# dsPIC33FJ64GS606 register map
Vendor: Microchip; Series: dsPIC33FJ64GS; File version: 1.4.228
Registers are 16-bit, read-write, no defined reset value unless marked. A register's access mark holds for its fields unless they carry their own. Offsets are from the block's base; [hi:lo] are bit positions; {n}, {i} and the like mark numbered series.

## PWM2 — PWM2 peripheral registers
Base 0x00000440
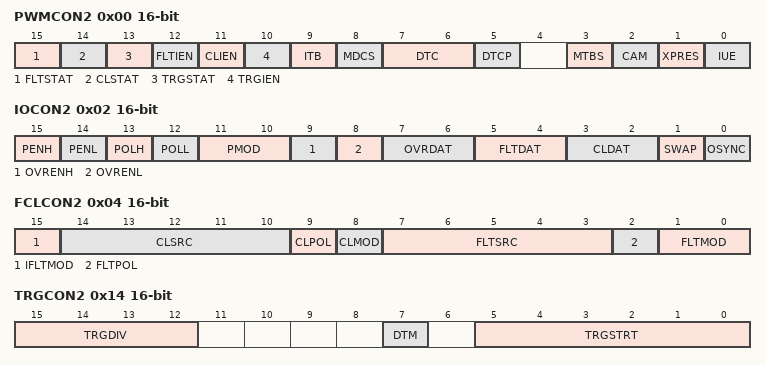
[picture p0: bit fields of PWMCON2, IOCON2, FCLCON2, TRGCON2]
0x00 PWMCON2
  [15] FLTSTAT — PWMCON2 field FLTSTAT
  [14] CLSTAT — PWMCON2 field CLSTAT
  [13] TRGSTAT — PWMCON2 field TRGSTAT
  [12] FLTIEN — PWMCON2 field FLTIEN
  [11] CLIEN — PWMCON2 field CLIEN
  [10] TRGIEN — PWMCON2 field TRGIEN
  [9] ITB — PWMCON2 field ITB
  [8] MDCS — PWMCON2 field MDCS
  [7:6] DTC — PWMCON2 field DTC
  [5] DTCP — PWMCON2 field DTCP
  [3] MTBS — PWMCON2 field MTBS
  [2] CAM — PWMCON2 field CAM
  [1] XPRES — PWMCON2 field XPRES
  [0] IUE — PWMCON2 field IUE
0x02 IOCON2
  [15] PENH — IOCON2 field PENH
  [14] PENL — IOCON2 field PENL
  [13] POLH — IOCON2 field POLH
  [12] POLL — IOCON2 field POLL
  [11:10] PMOD — IOCON2 field PMOD
  [9] OVRENH — IOCON2 field OVRENH
  [8] OVRENL — IOCON2 field OVRENL
  [7:6] OVRDAT — IOCON2 field OVRDAT
  [5:4] FLTDAT — IOCON2 field FLTDAT
  [3:2] CLDAT — IOCON2 field CLDAT
  [1] SWAP — IOCON2 field SWAP
  [0] OSYNC — IOCON2 field OSYNC
0x04 FCLCON2
  [15] IFLTMOD — FCLCON2 field IFLTMOD
  [14:10] CLSRC — FCLCON2 field CLSRC
  [9] CLPOL — FCLCON2 field CLPOL
  [8] CLMOD — FCLCON2 field CLMOD
  [7:3] FLTSRC — FCLCON2 field FLTSRC
  [2] FLTPOL — FCLCON2 field FLTPOL
  [1:0] FLTMOD — FCLCON2 field FLTMOD
0x06 PDC2
  [15:0] PDC2 — PDC2 register value
0x08 PHASE2
  [15:0] PHASE2 — PHASE2 register value
0x0A DTR2
  [13:0] DTR — DTR2 dead-time value
0x0C ALTDTR2
  [13:0] ALTDTR — ALTDTR2 dead-time value
0x0E SDC2
  [15:0] SDC2 — SDC2 register value
0x10 SPHASE2
  [15:0] SPHASE2 — SPHASE2 register value
0x12 TRIG2
  [15:3] TRGCMP — TRIG2 field TRGCMP
0x14 TRGCON2
  [15:12] TRGDIV — TRGCON2 field TRGDIV
  [7] DTM — TRGCON2 field DTM
  [5:0] TRGSTRT — TRGCON2 field TRGSTRT
0x16 STRIG2
  [15:3] STRGCMP — STRIG2 field STRGCMP
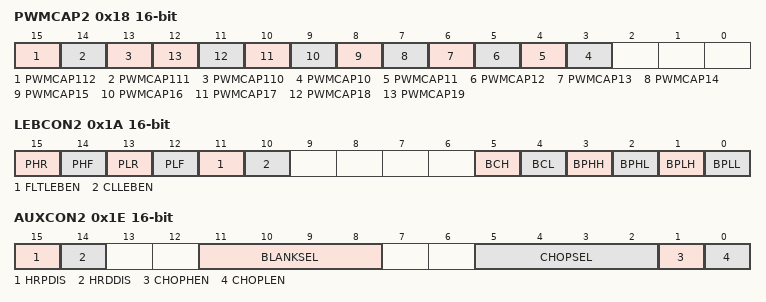
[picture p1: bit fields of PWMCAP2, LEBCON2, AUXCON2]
0x18 PWMCAP2
  [15] PWMCAP112 — PWMCAP2 field PWMCAP112
  [14] PWMCAP111 — PWMCAP2 field PWMCAP111
  [13] PWMCAP110 — PWMCAP2 field PWMCAP110
  [n-7] PWMCAP{n} (n=10..19) — PWMCAP2 field PWMCAP{n}
0x1A LEBCON2
  [15] PHR — LEBCON2 field PHR
  [14] PHF — LEBCON2 field PHF
  [13] PLR — LEBCON2 field PLR
  [12] PLF — LEBCON2 field PLF
  [11] FLTLEBEN — LEBCON2 field FLTLEBEN
  [10] CLLEBEN — LEBCON2 field CLLEBEN
  [5] BCH — LEBCON2 field BCH
  [4] BCL — LEBCON2 field BCL
  [3] BPHH — LEBCON2 field BPHH
  [2] BPHL — LEBCON2 field BPHL
  [1] BPLH — LEBCON2 field BPLH
  [0] BPLL — LEBCON2 field BPLL
0x1C LEBDLY2
  [11:3] LEB — LEBDLY2 field LEB
0x1E AUXCON2
  [15] HRPDIS — AUXCON2 field HRPDIS
  [14] HRDDIS — AUXCON2 field HRDDIS
  [11:8] BLANKSEL — AUXCON2 field BLANKSEL
  [5:2] CHOPSEL — AUXCON2 field CHOPSEL
  [1] CHOPHEN — AUXCON2 field CHOPHEN
  [0] CHOPLEN — AUXCON2 field CHOPLEN

## PWM3 — PWM3 peripheral registers
Base 0x00000460
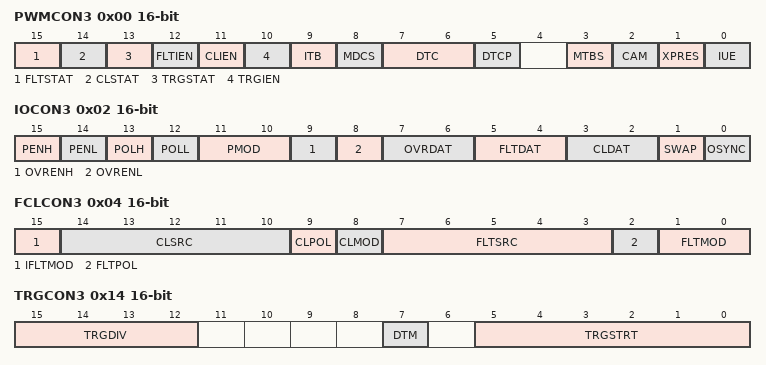
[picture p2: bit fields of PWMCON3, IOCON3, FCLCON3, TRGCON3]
0x00 PWMCON3
  [15] FLTSTAT — PWMCON3 field FLTSTAT
  [14] CLSTAT — PWMCON3 field CLSTAT
  [13] TRGSTAT — PWMCON3 field TRGSTAT
  [12] FLTIEN — PWMCON3 field FLTIEN
  [11] CLIEN — PWMCON3 field CLIEN
  [10] TRGIEN — PWMCON3 field TRGIEN
  [9] ITB — PWMCON3 field ITB
  [8] MDCS — PWMCON3 field MDCS
  [7:6] DTC — PWMCON3 field DTC
  [5] DTCP — PWMCON3 field DTCP
  [3] MTBS — PWMCON3 field MTBS
  [2] CAM — PWMCON3 field CAM
  [1] XPRES — PWMCON3 field XPRES
  [0] IUE — PWMCON3 field IUE
0x02 IOCON3
  [15] PENH — IOCON3 field PENH
  [14] PENL — IOCON3 field PENL
  [13] POLH — IOCON3 field POLH
  [12] POLL — IOCON3 field POLL
  [11:10] PMOD — IOCON3 field PMOD
  [9] OVRENH — IOCON3 field OVRENH
  [8] OVRENL — IOCON3 field OVRENL
  [7:6] OVRDAT — IOCON3 field OVRDAT
  [5:4] FLTDAT — IOCON3 field FLTDAT
  [3:2] CLDAT — IOCON3 field CLDAT
  [1] SWAP — IOCON3 field SWAP
  [0] OSYNC — IOCON3 field OSYNC
0x04 FCLCON3
  [15] IFLTMOD — FCLCON3 field IFLTMOD
  [14:10] CLSRC — FCLCON3 field CLSRC
  [9] CLPOL — FCLCON3 field CLPOL
  [8] CLMOD — FCLCON3 field CLMOD
  [7:3] FLTSRC — FCLCON3 field FLTSRC
  [2] FLTPOL — FCLCON3 field FLTPOL
  [1:0] FLTMOD — FCLCON3 field FLTMOD
0x06 PDC3
  [15:0] PDC3 — PDC3 register value
0x08 PHASE3
  [15:0] PHASE3 — PHASE3 register value
0x0A DTR3
  [13:0] DTR — DTR3 dead-time value
0x0C ALTDTR3
  [13:0] ALTDTR — ALTDTR3 dead-time value
0x0E SDC3
  [15:0] SDC3 — SDC3 register value
0x10 SPHASE3
  [15:0] SPHASE3 — SPHASE3 register value
0x12 TRIG3
  [15:3] TRGCMP — TRIG3 field TRGCMP
0x14 TRGCON3
  [15:12] TRGDIV — TRGCON3 field TRGDIV
  [7] DTM — TRGCON3 field DTM
  [5:0] TRGSTRT — TRGCON3 field TRGSTRT
0x16 STRIG3
  [15:3] STRGCMP — STRIG3 field STRGCMP
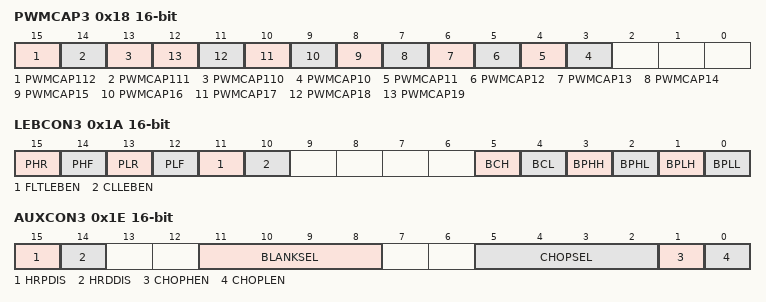
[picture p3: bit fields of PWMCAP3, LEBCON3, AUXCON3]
0x18 PWMCAP3
  [15] PWMCAP112 — PWMCAP3 field PWMCAP112
  [14] PWMCAP111 — PWMCAP3 field PWMCAP111
  [13] PWMCAP110 — PWMCAP3 field PWMCAP110
  [n-7] PWMCAP{n} (n=10..19) — PWMCAP3 field PWMCAP{n}
0x1A LEBCON3
  [15] PHR — LEBCON3 field PHR
  [14] PHF — LEBCON3 field PHF
  [13] PLR — LEBCON3 field PLR
  [12] PLF — LEBCON3 field PLF
  [11] FLTLEBEN — LEBCON3 field FLTLEBEN
  [10] CLLEBEN — LEBCON3 field CLLEBEN
  [5] BCH — LEBCON3 field BCH
  [4] BCL — LEBCON3 field BCL
  [3] BPHH — LEBCON3 field BPHH
  [2] BPHL — LEBCON3 field BPHL
  [1] BPLH — LEBCON3 field BPLH
  [0] BPLL — LEBCON3 field BPLL
0x1C LEBDLY3
  [11:3] LEB — LEBDLY3 field LEB
0x1E AUXCON3
  [15] HRPDIS — AUXCON3 field HRPDIS
  [14] HRDDIS — AUXCON3 field HRDDIS
  [11:8] BLANKSEL — AUXCON3 field BLANKSEL
  [5:2] CHOPSEL — AUXCON3 field CHOPSEL
  [1] CHOPHEN — AUXCON3 field CHOPHEN
  [0] CHOPLEN — AUXCON3 field CHOPLEN
